AUTOSAR XML (schema 4-0-3)
standard types defined: UInt32, UInt8
package /AUTOSAR_Platform/DataConstrs
  range DC_UInt8: raw 0..255
package /PATAC/MSM/ComponentTypes
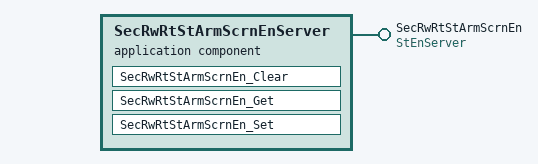
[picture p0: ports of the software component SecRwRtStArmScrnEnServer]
  application sw component type SecRwRtStArmScrnEnServer
    provide port SecRwRtStArmScrnEn: provided-com-specs=[{operation=Clear, queue-length=1}, {operation=Get, queue-length=1}, {operation=Set, queue-length=1}], provided-interface=StEnServer
    behavior SecRwRtStArmScrnEnServer_InternalBehavior
      operation invoked event OIT_SecRwRtStArmScrnEn_Clear_SecRwRtStArmScrnEn_Clear: start-on-event=SecRwRtStArmScrnEn_Clear, operation=SecRwRtStArmScrnEn.Clear
      operation invoked event OIT_SecRwRtStArmScrnEn_Get_SecRwRtStArmScrnEn_Get: start-on-event=SecRwRtStArmScrnEn_Get, operation=SecRwRtStArmScrnEn.Get
      operation invoked event OIT_SecRwRtStArmScrnEn_Set_SecRwRtStArmScrnEn_Set: start-on-event=SecRwRtStArmScrnEn_Set, operation=SecRwRtStArmScrnEn.Set
      runnable SecRwRtStArmScrnEn_Clear
      runnable SecRwRtStArmScrnEn_Get
      runnable SecRwRtStArmScrnEn_Set
  swc implementation SecRwRtStArmScrnEnServer_Implementation: behavior=SecRwRtStArmScrnEnServer_InternalBehavior
    code-descriptors:
      code Default: artifact-descriptors=autosar-engineering-object={short-label=Default, category=SWSRC}
package /PATAC/MSM/ModeAdjust/PortInterface
  client server interface StEnServer
    operation Clear
      arg data: type=UInt8, direction=IN, server-argument-impl-policy=USE-ARGUMENT-TYPE
    operation Get
      arg data: type=UInt32, direction=OUT, server-argument-impl-policy=USE-ARGUMENT-TYPE
    operation Set
      arg data: type=UInt8, direction=IN, server-argument-impl-policy=USE-ARGUMENT-TYPE
